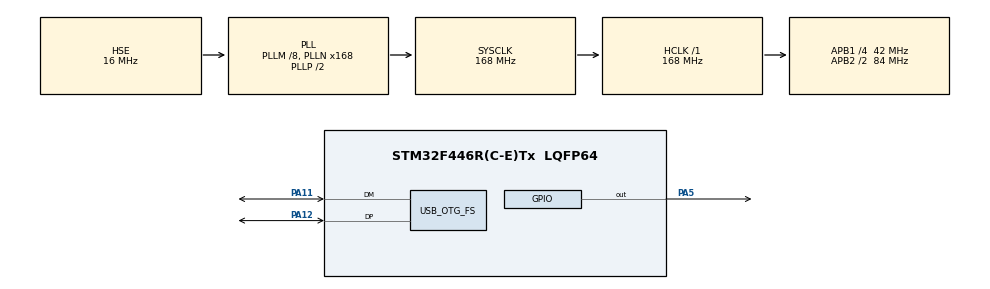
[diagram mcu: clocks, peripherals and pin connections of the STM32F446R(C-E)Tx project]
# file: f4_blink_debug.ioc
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Mcu.Family=STM32F4
Mcu.Name=STM32F446R(C-E)Tx
Mcu.Package=LQFP64
NVIC.OTG_FS_IRQn=true\:0\:0\:false\:false\:true\:false\:true
NVIC.PriorityGroup=NVIC_PRIORITYGROUP_4
PA11.Mode=Device_Only
PA11.Signal=USB_OTG_FS_DM
PA12.Mode=Device_Only
PA12.Signal=USB_OTG_FS_DP
PA13.Mode=Trace_Asynchronous_SW
PA13.Signal=SYS_JTMS-SWDIO
PA14.Mode=Trace_Asynchronous_SW
PA14.Signal=SYS_JTCK-SWCLK
PA5.Signal=GPIO_Output
PB3.Mode=Trace_Asynchronous_SW
PB3.Signal=SYS_JTDO-SWO
PH0-OSC_IN.Mode=HSE-External-Oscillator
PH0-OSC_IN.Signal=RCC_OSC_IN
PH1-OSC_OUT.Mode=HSE-External-Oscillator
PH1-OSC_OUT.Signal=RCC_OSC_OUT
ProjectManager.HeapSize=0x200
ProjectManager.StackSize=0x400
ProjectManager.TargetToolchain=STM32CubeIDE
RCC.AHBFreq_Value=168000000
RCC.APB1CLKDivider=RCC_HCLK_DIV4
RCC.APB1Freq_Value=42000000
RCC.APB1TimFreq_Value=84000000
RCC.APB2CLKDivider=RCC_HCLK_DIV2
RCC.APB2Freq_Value=84000000
RCC.APB2TimFreq_Value=168000000
RCC.CortexFreq_Value=168000000
RCC.HCLKFreq_Value=168000000
RCC.HSE_VALUE=16000000
RCC.PLLM=8
RCC.PLLN=168
RCC.PLLQ=7
RCC.SYSCLKFreq_VALUE=168000000
RCC.SYSCLKSource=RCC_SYSCLKSOURCE_PLLCLK
RCC.USBFreq_Value=48000000
RCC.VCOOutputFreq_Value=336000000
USB_DEVICE.CLASS_NAME_FS=CDC
USB_DEVICE.VirtualMode-CDC_FS=Cdc
USB_DEVICE.VirtualModeFS=Cdc_FS
USB_OTG_FS.VirtualMode=Device_Only
VP_USB_DEVICE_VS_USB_DEVICE_CDC_FS.Mode=CDC_FS
board=custom

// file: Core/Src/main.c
/* USER CODE BEGIN Header */
/**
  ******************************************************************************
  * @file           : main.c
  * @brief          : Main program body
  ******************************************************************************
  * @attention
  *
  * <h2><center>&copy; Copyright (c) 2020 STMicroelectronics.
  * All rights reserved.</center></h2>
  *
  * This software component is licensed by ST under BSD 3-Clause license,
  * the "License"; You may not use this file except in compliance with the
  * License. You may obtain a copy of the License at:
  *                        opensource.org/licenses/BSD-3-Clause
  *
  ******************************************************************************
  */
/* USER CODE END Header */
#include "main.h"
#include "usb_device.h"
#include "usbd_cdc.h"

void SystemClock_Config(void);
static void MX_GPIO_Init(void);

int main(void)
{

  /* MCU Configuration--------------------------------------------------------*/

  /* Reset of all peripherals, Initializes the Flash interface and the Systick. */
  HAL_Init();

  /* Configure the system clock */
  SystemClock_Config();

  /* Initialize all configured peripherals */
  MX_GPIO_Init();
  MX_USB_DEVICE_Init();

  /* Infinite loop */
  while (1)
  {

    /* USER CODE BEGIN 3 */
	  HAL_Delay(203);
	  HAL_GPIO_TogglePin(GPIOA, GPIO_PIN_5);
//	  USART2->DR = 48;
//	  CDC_Transmit_FS("hello\n", 6);
	  USBD_CDC_SetTxBuffer(USBD_HandleTypeDef *pdev, uint8_t *pbuff,
	                               uint32_t length);
  }
  /* USER CODE END 3 */
}

void SystemClock_Config(void)
{
  RCC_OscInitTypeDef RCC_OscInitStruct = {0};
  RCC_ClkInitTypeDef RCC_ClkInitStruct = {0};
  RCC_PeriphCLKInitTypeDef PeriphClkInitStruct = {0};

  /** Configure the main internal regulator output voltage
  */
  __HAL_RCC_PWR_CLK_ENABLE();
  __HAL_PWR_VOLTAGESCALING_CONFIG(PWR_REGULATOR_VOLTAGE_SCALE1);
  /** Initializes the RCC Oscillators according to the specified parameters
  * in the RCC_OscInitTypeDef structure.
  */
  RCC_OscInitStruct.OscillatorType = RCC_OSCILLATORTYPE_HSE;
  RCC_OscInitStruct.HSEState = RCC_HSE_ON;
  RCC_OscInitStruct.PLL.PLLState = RCC_PLL_ON;
  RCC_OscInitStruct.PLL.PLLSource = RCC_PLLSOURCE_HSE;
  RCC_OscInitStruct.PLL.PLLM = 8;
  RCC_OscInitStruct.PLL.PLLN = 168;
  RCC_OscInitStruct.PLL.PLLP = RCC_PLLP_DIV2;
  RCC_OscInitStruct.PLL.PLLQ = 7;
  RCC_OscInitStruct.PLL.PLLR = 2;
  if (HAL_RCC_OscConfig(&RCC_OscInitStruct) != HAL_OK)
  {
    Error_Handler();
  }
  /** Initializes the CPU, AHB and APB buses clocks
  */
  RCC_ClkInitStruct.ClockType = RCC_CLOCKTYPE_HCLK|RCC_CLOCKTYPE_SYSCLK
                              |RCC_CLOCKTYPE_PCLK1|RCC_CLOCKTYPE_PCLK2;
  RCC_ClkInitStruct.SYSCLKSource = RCC_SYSCLKSOURCE_PLLCLK;
  RCC_ClkInitStruct.AHBCLKDivider = RCC_SYSCLK_DIV1;
  RCC_ClkInitStruct.APB1CLKDivider = RCC_HCLK_DIV4;
  RCC_ClkInitStruct.APB2CLKDivider = RCC_HCLK_DIV2;

  if (HAL_RCC_ClockConfig(&RCC_ClkInitStruct, FLASH_LATENCY_5) != HAL_OK)
  {
    Error_Handler();
  }
  PeriphClkInitStruct.PeriphClockSelection = RCC_PERIPHCLK_CLK48;
  PeriphClkInitStruct.Clk48ClockSelection = RCC_CLK48CLKSOURCE_PLLQ;
  if (HAL_RCCEx_PeriphCLKConfig(&PeriphClkInitStruct) != HAL_OK)
  {
    Error_Handler();
  }
}

static void MX_GPIO_Init(void)
{
  GPIO_InitTypeDef GPIO_InitStruct = {0};

  /* GPIO Ports Clock Enable */
  __HAL_RCC_GPIOH_CLK_ENABLE();
  __HAL_RCC_GPIOA_CLK_ENABLE();
  __HAL_RCC_GPIOB_CLK_ENABLE();

  /*Configure GPIO pin Output Level */
  HAL_GPIO_WritePin(GPIOA, GPIO_PIN_5, GPIO_PIN_RESET);

  /*Configure GPIO pin : PA5 */
  GPIO_InitStruct.Pin = GPIO_PIN_5;
  GPIO_InitStruct.Mode = GPIO_MODE_OUTPUT_PP;
  GPIO_InitStruct.Pull = GPIO_NOPULL;
  GPIO_InitStruct.Speed = GPIO_SPEED_FREQ_LOW;
  HAL_GPIO_Init(GPIOA, &GPIO_InitStruct);

}

void Error_Handler(void)
{
}

/************************ (C) COPYRIGHT STMicroelectronics *****END OF FILE****/
